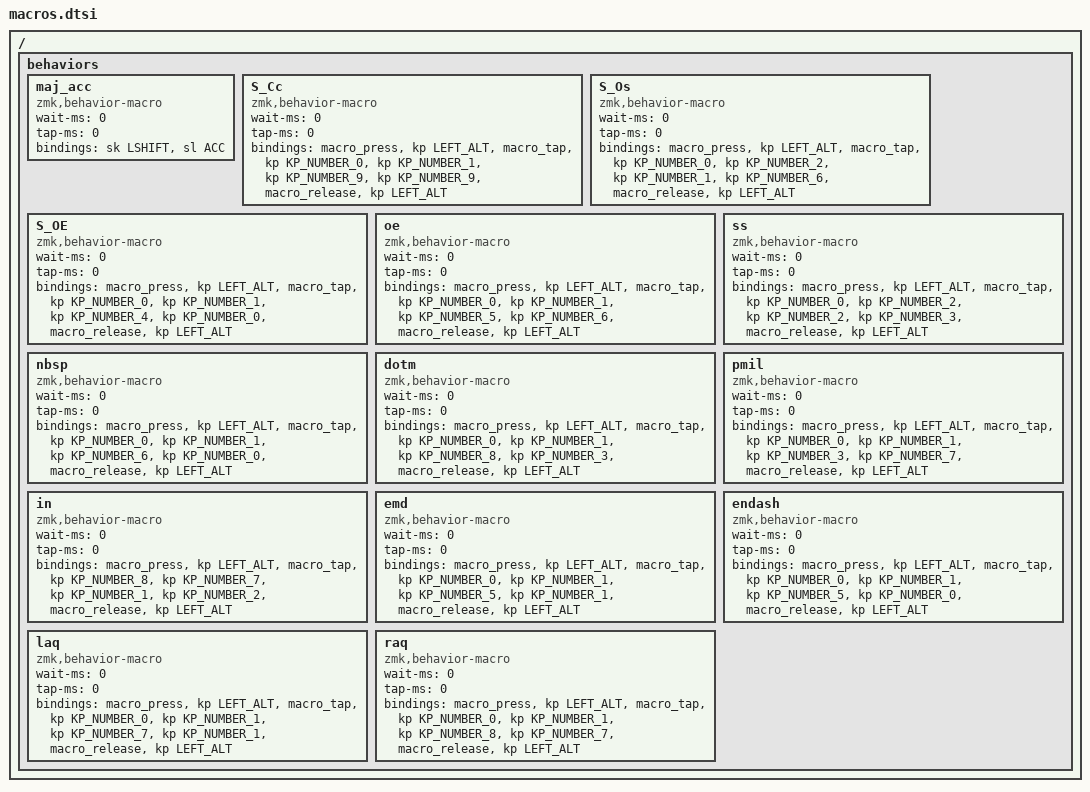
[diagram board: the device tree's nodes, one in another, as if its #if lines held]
#include "layout.h"
#include <behaviors.dtsi>
#include <dt-bindings/zmk/keys.h>

/ {
  behaviors {

    /* =========================
     * Dead + space (utile)
     * ========================= */


    maj_acc: maj_acc {
        compatible = "zmk,behavior-macro";
        #binding-cells = <0>;
        wait-ms = <0>;
        tap-ms = <0>;
        bindings = <&sk LSHIFT>, <&sl ACC>;
    };

#if defined(DULLBOY_TEXT_CH_FR)
#include "host/text_ch_fr.dtsi"
#elif defined(DULLBOY_TEXT_WINDOWS)
#include "host/text_windows.dtsi"
#else
#error "Select a supported host text backend in layout.h"
#endif

    S_Cc: S_Cc {
      compatible = "zmk,behavior-macro";
      #binding-cells = <0>;
      wait-ms = <0>;
      tap-ms = <0>;
      bindings = <
        &macro_press &kp LEFT_ALT
        &macro_tap &kp KP_NUMBER_0 &kp KP_NUMBER_1 &kp KP_NUMBER_9 &kp KP_NUMBER_9
        &macro_release &kp LEFT_ALT
      >;
    };

    S_Os: S_Os {
      compatible = "zmk,behavior-macro";
      #binding-cells = <0>;
      wait-ms = <0>;
      tap-ms = <0>;
      bindings = <
        &macro_press &kp LEFT_ALT
        &macro_tap &kp KP_NUMBER_0 &kp KP_NUMBER_2 &kp KP_NUMBER_1 &kp KP_NUMBER_6
        &macro_release &kp LEFT_ALT
      >;
    };

    S_OE: S_OE {
      compatible = "zmk,behavior-macro";
      #binding-cells = <0>;
      wait-ms = <0>;
      tap-ms = <0>;
      bindings = <
        &macro_press &kp LEFT_ALT
        &macro_tap &kp KP_NUMBER_0 &kp KP_NUMBER_1 &kp KP_NUMBER_4 &kp KP_NUMBER_0
        &macro_release &kp LEFT_ALT
      >;
    };

    oe: oe {
      compatible = "zmk,behavior-macro";
      #binding-cells = <0>;
      wait-ms = <0>;
      tap-ms = <0>;
      bindings = <
        &macro_press &kp LEFT_ALT
        &macro_tap &kp KP_NUMBER_0 &kp KP_NUMBER_1 &kp KP_NUMBER_5 &kp KP_NUMBER_6
        &macro_release &kp LEFT_ALT
      >;
    };

    ss: ss {
      compatible = "zmk,behavior-macro";
      #binding-cells = <0>;
      wait-ms = <0>;
      tap-ms = <0>;
      bindings = <
        &macro_press &kp LEFT_ALT
        &macro_tap &kp KP_NUMBER_0 &kp KP_NUMBER_2 &kp KP_NUMBER_2 &kp KP_NUMBER_3
        &macro_release &kp LEFT_ALT
      >;
    };

    nbsp: nbsp {
      compatible = "zmk,behavior-macro";
      #binding-cells = <0>;
      wait-ms = <0>;
      tap-ms = <0>;
      bindings = <
        &macro_press &kp LEFT_ALT
        &macro_tap &kp KP_NUMBER_0 &kp KP_NUMBER_1 &kp KP_NUMBER_6 &kp KP_NUMBER_0
        &macro_release &kp LEFT_ALT
      >;
    };

    dotm: dotm {
      compatible = "zmk,behavior-macro";
      #binding-cells = <0>;
      wait-ms = <0>;
      tap-ms = <0>;
      bindings = <
        &macro_press &kp LEFT_ALT
        &macro_tap &kp KP_NUMBER_0 &kp KP_NUMBER_1 &kp KP_NUMBER_8 &kp KP_NUMBER_3
        &macro_release &kp LEFT_ALT
      >;
    };

    pmil: pmil {
      compatible = "zmk,behavior-macro";
      #binding-cells = <0>;
      wait-ms = <0>;
      tap-ms = <0>;
      bindings = <
        &macro_press &kp LEFT_ALT
        &macro_tap &kp KP_NUMBER_0 &kp KP_NUMBER_1 &kp KP_NUMBER_3 &kp KP_NUMBER_7
        &macro_release &kp LEFT_ALT
      >;
    };

    in: in {
      compatible = "zmk,behavior-macro";
      #binding-cells = <0>;
      wait-ms = <0>;
      tap-ms = <0>;
      bindings = <
        &macro_press &kp LEFT_ALT
        &macro_tap &kp KP_NUMBER_8 &kp KP_NUMBER_7 &kp KP_NUMBER_1 &kp KP_NUMBER_2
        &macro_release &kp LEFT_ALT
      >;
    };

    emd: emd {
      compatible = "zmk,behavior-macro";
      #binding-cells = <0>;
      wait-ms = <0>;
      tap-ms = <0>;
      bindings = <
        &macro_press &kp LEFT_ALT
        &macro_tap &kp KP_NUMBER_0 &kp KP_NUMBER_1 &kp KP_NUMBER_5 &kp KP_NUMBER_1
        &macro_release &kp LEFT_ALT
      >;
    };

    endash: endash {
      compatible = "zmk,behavior-macro";
      #binding-cells = <0>;
      wait-ms = <0>;
      tap-ms = <0>;
      bindings = <
        &macro_press &kp LEFT_ALT
        &macro_tap &kp KP_NUMBER_0 &kp KP_NUMBER_1 &kp KP_NUMBER_5 &kp KP_NUMBER_0
        &macro_release &kp LEFT_ALT
      >;
    };

    laq: laq {
      compatible = "zmk,behavior-macro";
      #binding-cells = <0>;
      wait-ms = <0>;
      tap-ms = <0>;
      bindings = <
        &macro_press &kp LEFT_ALT
        &macro_tap &kp KP_NUMBER_0 &kp KP_NUMBER_1 &kp KP_NUMBER_7 &kp KP_NUMBER_1
        &macro_release &kp LEFT_ALT
      >;
    };

    raq: raq {
      compatible = "zmk,behavior-macro";
      #binding-cells = <0>;
      wait-ms = <0>;
      tap-ms = <0>;
      bindings = <
        &macro_press &kp LEFT_ALT
        &macro_tap &kp KP_NUMBER_0 &kp KP_NUMBER_1 &kp KP_NUMBER_8 &kp KP_NUMBER_7
        &macro_release &kp LEFT_ALT
      >;
    };
  };
};

#include "mdp.dtsi"
